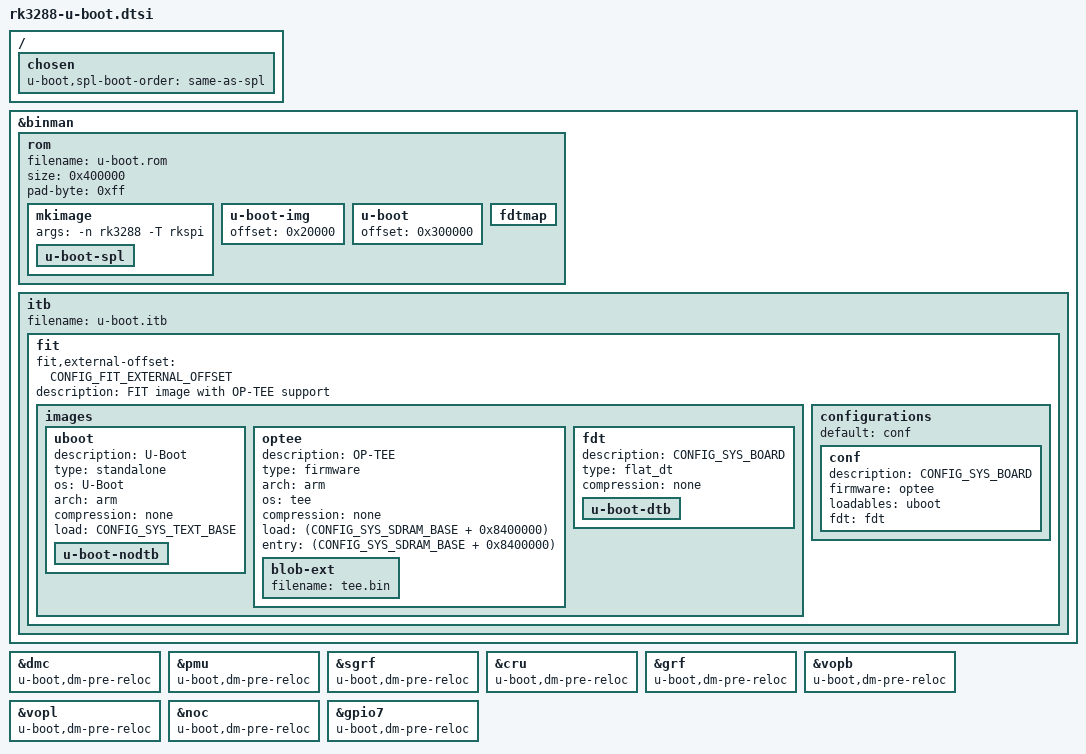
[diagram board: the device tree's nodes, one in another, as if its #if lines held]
// SPDX-License-Identifier: GPL-2.0+
/*
 * Copyright (C) 2019 Rockchip Electronics Co., Ltd
 */

#include "rockchip-u-boot.dtsi"

/ {
	chosen {
		u-boot,spl-boot-order = \
			"same-as-spl", &emmc, &sdmmc;
	};
};

#ifdef CONFIG_HAS_ROM
&binman {
	rom {
		filename = "u-boot.rom";
		size = <0x400000>;
		pad-byte = <0xff>;

		mkimage {
			args = "-n rk3288 -T rkspi";
			u-boot-spl {
			};
		};
		u-boot-img {
			offset = <0x20000>;
		};
		u-boot {
			offset = <0x300000>;
		};
		fdtmap {
		};
	};

	itb {
		filename = "u-boot.itb";
		fit {
			fit,external-offset = <CONFIG_FIT_EXTERNAL_OFFSET>;
			description = "FIT image with OP-TEE support";
			#address-cells = <1>;

			images {
				uboot {
					description = "U-Boot";
					type = "standalone";
					os = "U-Boot";
					arch = "arm";
					compression = "none";
					load = <CONFIG_SYS_TEXT_BASE>;

					u-boot-nodtb {
					};
				};
				optee {
					description = "OP-TEE";
					type = "firmware";
					arch = "arm";
					os = "tee";
					compression = "none";
					load = <(CONFIG_SYS_SDRAM_BASE + 0x8400000)>;
					entry = <(CONFIG_SYS_SDRAM_BASE + 0x8400000)>;

					blob-ext {
						filename = "tee.bin";
					};
				};
				fdt {
					description = CONFIG_SYS_BOARD;
					type = "flat_dt";
					compression = "none";

					u-boot-dtb {
					};
				};
			};

			configurations {
				default = "conf";
				conf {
					description = CONFIG_SYS_BOARD;
					firmware = "optee";
					loadables = "uboot";
					fdt = "fdt";
				};
			};
		};
	};
};
#endif

&dmc {
	u-boot,dm-pre-reloc;
};

&pmu {
	u-boot,dm-pre-reloc;
};

&sgrf {
	u-boot,dm-pre-reloc;
};

&cru {
	u-boot,dm-pre-reloc;
};

&grf {
	u-boot,dm-pre-reloc;
};

&vopb {
	u-boot,dm-pre-reloc;
};

&vopl {
	u-boot,dm-pre-reloc;
};

&noc {
	u-boot,dm-pre-reloc;
};

&gpio7 {
	u-boot,dm-pre-reloc;
};
